VERSION ""

NS_ :

BS_: 500

BU_: Vector__XXX

BO_ 64 MSG_040: 8 Vector__XXX
 SG_ Engine_Speed : 16|15@1+ (1,0) [0|32767] "rpm" Vector__XXX
 SG_ Accelerator_Pedal_Position : 24|8@0+ (0.3921,0) [0|99.9855] "%" Vector__XXX

BO_ 312 MSG_138: 8 Vector__XXX
 SG_ Steering_Angle : 16|16@1- (0.1,0) [-3276.8|3276.7] "��" Vector__XXX

BO_ 313 MSG_139: 8 Vector__XXX
 SG_ Brake_Position : 16|8@0+ (0.6,0) [0|153] "%" Vector__XXX

BO_ 808 MSG_328: 8 Vector__XXX
 SG_ Race_Mode : 38|1@0+ (1,0) [0|1] "on/off" Vector__XXX

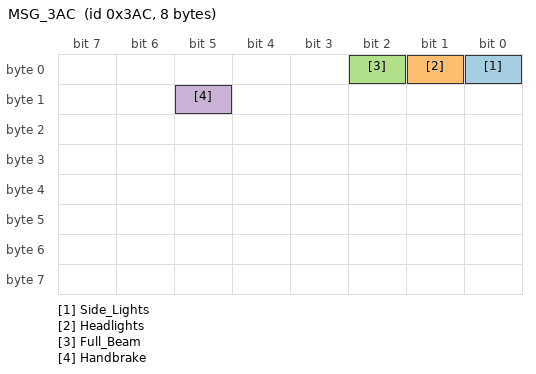
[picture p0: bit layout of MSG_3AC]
BO_ 940 MSG_3AC: 8 Vector__XXX
 SG_ Side_Lights : 0|1@0+ (1,0) [0|1] "on/off" Vector__XXX
 SG_ Headlights : 1|1@0+ (1,0) [0|1] "on/off" Vector__XXX
 SG_ Full_Beam : 2|1@0+ (1,0) [0|1] "on/off" Vector__XXX
 SG_ Handbrake : 13|1@0+ (1,0) [0|1] "on/off" Vector__XXX
